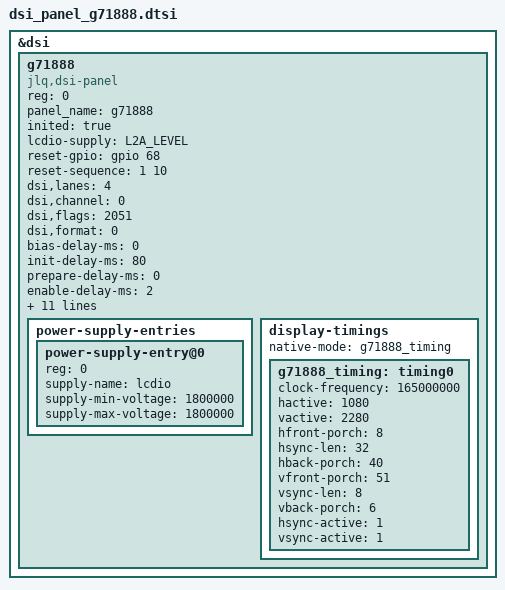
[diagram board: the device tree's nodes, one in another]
&dsi {
	g71888: g71888 {
		compatible = "jlq,dsi-panel";
		reg = <0>;
		panel_name = "g71888";
		status = "okay";
		inited = "true";

		lcdio-supply = <&L2A_LEVEL>;
		//lcdcore-supply = <&dldo13>;
		//bias-enp-gpio = <&gpio 2 0>;
		reset-gpio = <&gpio 68 0>;
		//bias-enn-gpio = <&gpio 0 0>;
		reset-sequence = <1 10>;
		pinctrl-names = "default";
		//pinctrl-0 = <&lcd_reset_pin>;

		dsi,lanes = <4>;
		dsi,channel = <0>;
		dsi,flags = <2051>;
		dsi,format = <0>;

		bias-delay-ms = <0>;
		init-delay-ms = <80>;
		prepare-delay-ms = <0>;
		enable-delay-ms = <2>;
		unprepare-delay-ms = <0>;
		disable-delay-ms = <2>;
		reset-delay-ms = <80>;
		width-mm = <120>;
		height-mm = <170>;
		pwm-names = "backlight";
		pwms = <&pwm0 0 32000>;

		panel-exit-sequence = [
			05 05 01 28
			05 78 01 10
		];

		panel-init-sequence = [
			39 01 04 df e0 94 31
			39 01 04 df e0 9e 51
			39 01 04 df e0 9f 48
			39 01 04 df e0 fb 0b
			39 01 04 df e4 a6 55
			39 01 04 df e0 94 00
			39 01 04 df e7 e3 aa
			39 01 04 df e7 e4 0a
			39 01 04 df e7 e5 22
			39 01 04 df e7 e6 aa
			39 01 04 df e7 e7 0a
			39 01 04 df e7 e8 22
			39 01 04 df e7 de d6
			39 01 04 df e7 d7 15
			39 01 04 df e7 d8 05
			39 01 04 df e4 84 10
			39 01 04 df e4 85 10
			39 01 04 df e4 60 12
			39 01 04 df e4 61 12
			39 01 04 df e4 65 12
			39 01 04 df e4 66 12
			39 01 04 df e7 bd 03
			39 01 04 df e7 be 03
			39 01 04 df e7 bf 03
			39 01 04 df e7 c0 03
			39 01 04 df e7 c1 03
			39 01 04 df e7 c2 03
			39 01 04 df e7 c3 03
			39 01 04 df e7 c4 03
			39 01 04 df e2 03 01
			39 01 04 df e2 04 01
			39 01 04 df e2 05 01
			39 01 04 df e2 0d 26
			39 01 04 df e2 0e 27
			39 01 04 df e2 08 a0
			39 01 04 df e2 0a cb
			39 01 04 df e2 07 a6
			39 01 04 df e2 09 cb
			39 01 04 df e2 16 00
			39 01 04 df e2 13 0e
			39 01 04 df e7 f4 49

			//gamma start
			39 01 04 df e4 20 04
			39 01 04 df e4 21 0b
			39 01 04 df e4 22 30
			39 01 04 df e4 23 3F
			39 01 04 df e4 24 0b
			39 01 04 df e4 25 14
			39 01 04 df e4 26 1C
			39 01 04 df e4 27 22
			39 01 04 df e4 28 2e
			39 01 04 df e4 29 38
			39 01 04 df e4 2a 2C
			39 01 04 df e4 2b 07
			39 01 04 df e4 2c 11
			39 01 04 df e4 2d 21
			39 01 04 df e4 2e 23
			39 01 04 df e4 2f 31
			39 01 04 df e4 30 38
			39 01 04 df e4 31 1f
			39 01 04 df e4 32 09
			39 01 04 df e4 33 14
			39 01 04 df e4 34 1e
			39 01 04 df e4 35 25
			39 01 04 df e4 36 2C
			39 01 04 df e4 37 35
			39 01 04 df e4 38 31
			39 01 04 df e4 39 35
			39 01 04 df e4 3a 37
			39 01 04 df e4 40 04
			39 01 04 df e4 41 0b
			39 01 04 df e4 42 30
			39 01 04 df e4 43 3F
			39 01 04 df e4 44 0b
			39 01 04 df e4 45 14
			39 01 04 df e4 46 1C
			39 01 04 df e4 47 22
			39 01 04 df e4 48 2e
			39 01 04 df e4 49 38
			39 01 04 df e4 4a 2C
			39 01 04 df e4 4b 07
			39 01 04 df e4 4c 11
			39 01 04 df e4 4d 21
			39 01 04 df e4 4e 23
			39 01 04 df e4 4f 31
			39 01 04 df e4 50 38
			39 01 04 df e4 51 1f
			39 01 04 df e4 52 09
			39 01 04 df e4 53 14
			39 01 04 df e4 54 1e
			39 01 04 df e4 55 25
			39 01 04 df e4 56 2C
			39 01 04 df e4 57 35
			39 01 04 df e4 58 31
			39 01 04 df e4 59 35
			39 01 04 df e4 5a 37
			//gamma end

			39 01 04 df e2 17 3e
			39 01 04 df e2 18 20
			39 01 04 df e2 48 80
			39 01 04 df e2 2f 00
			39 01 04 df e2 30 00
			39 01 04 df e2 3c 00
			39 01 04 df e2 3d 00
			39 01 04 df e0 06 06
			39 01 04 df e0 0a 88
			39 01 04 df e0 0b 04
			39 01 04 df e0 0c 48
			39 01 04 df e0 0d 00
			39 01 04 df e0 0e 38
			39 01 04 df e0 0f 04
			39 01 04 df e0 10 29
			39 01 04 df e0 11 09
			39 01 04 df e0 12 0e
			39 01 04 df e0 13 00
			39 01 04 df e0 14 e8
			39 01 04 df e0 15 08
			39 01 04 df e0 16 0a
			39 01 04 df e0 17 c1
			39 01 04 df e0 18 00
			39 01 04 df e0 19 20
			39 01 04 df e0 1a 02
			39 01 04 df e0 1b bf
			39 01 04 df e0 1c 09
			39 01 04 df e0 1d ff
			39 01 04 df e0 1e 01
			39 01 04 df e0 1f 10
			39 01 04 df e0 20 00
			39 01 04 df e0 26 bf
			39 01 04 df e0 28 00
			39 01 04 df e0 29 13
			39 01 04 df e0 2a 02
			39 01 04 df e1 92 1c
			39 01 04 df e1 93 01
			39 01 04 df e1 94 20
			39 01 04 df e1 95 01
			39 01 04 df e1 96 0c
			39 01 04 df e1 97 01
			39 01 04 df e1 b5 00
			39 01 04 df e1 a9 02
			39 01 04 df e1 aa 00
			39 01 04 df e1 ab 00
			39 01 04 df e1 ac 06
			39 01 04 df e1 ad 28
			39 01 04 df e1 ae 28
			39 01 04 df e1 af 28
			39 01 04 df e1 bd 0b
			39 01 04 df e1 be 0b
			39 01 04 df e1 99 4c
			39 01 04 df e1 b4 c4
			39 01 04 df e1 a8 00
			39 01 04 df e1 cb 1c
			39 01 04 df e1 cc 10
			39 01 04 df e1 ce 20
			39 01 04 df e1 cd 07
			39 01 04 df e1 98 03
			39 01 04 df e1 d6 03
			39 01 04 df e1 c9 09
			39 01 04 df e1 ed 10
			39 01 04 df e1 d9 00
			39 01 04 df e1 da 00
			39 01 04 df e1 db 00
			39 01 04 df e1 9b 10
			39 01 04 df e1 9c c0
			39 01 04 df e1 9d 04
			39 01 04 df e1 81 a0
			39 01 04 df e1 82 02
			39 01 04 df e1 83 00
			39 01 04 df e1 84 03
			39 01 04 df e1 85 60
			39 01 04 df e1 86 03
			39 01 04 df e1 9e 00
			39 01 04 df e1 9f 03
			39 01 04 df e1 a0 08
			39 01 04 df e1 b1 66
			39 01 04 df e1 ca 22
			39 01 04 df e1 87 e8
			39 01 04 df e1 88 08
			39 01 04 df e1 89 29
			39 01 04 df e1 8a 09
			39 01 04 df e1 d7 45
			39 01 04 df e1 d8 00
			39 01 04 df e1 89 a0
			39 01 04 df e1 8a 07
			39 01 04 df e1 8b 0e
			39 01 04 df e1 8c 00
			39 01 04 df e1 ee f0
			39 01 04 df e1 8f 88
			39 01 04 df e1 90 04
			39 01 04 df e7 af 77
			39 01 04 df e7 ae 02
			39 01 04 df e7 6a 40
			39 01 04 df e7 00 13
			39 01 04 df e7 01 10
			39 01 04 df e7 02 27
			39 01 04 df e7 73 11
			39 01 04 df e7 74 22
			39 01 04 df e7 75 11
			39 01 04 df e7 76 00
			39 01 04 df e7 77 22
			39 01 04 df e7 78 11
			39 01 04 df e7 79 00
			39 01 04 df e7 7a 00
			39 01 04 df e7 7b 11
			39 01 04 df e7 7c 22
			39 01 04 df e7 7d 00
			39 01 04 df e7 7e 11
			39 01 04 df e7 7f 22
			39 01 04 df e7 50 0c
			39 01 04 df e7 51 0d
			39 01 04 df e7 71 30
			39 01 04 df e7 5c 00
			39 01 04 df e7 5d 00
			39 01 04 df e7 60 10
			39 01 04 df e7 61 00
			39 01 04 df e7 62 00
			39 01 04 df e7 6b 00
			39 01 04 df e2 47 17
			39 01 04 df e7 70 28
			39 01 04 df e7 52 00
			39 01 04 df e7 0b 0c
			39 01 04 df e7 0c 66
			39 01 04 df e7 17 00
			39 01 04 df e7 0d 66
			39 01 04 df e7 0e c0
			39 01 04 df e7 18 00
			39 01 04 df e7 0f c0
			39 01 04 df e7 10 1a
			39 01 04 df e7 19 01
			39 01 04 df e7 11 0c
			39 01 04 df e7 12 66
			39 01 04 df e7 1a 00
			39 01 04 df e7 13 66
			39 01 04 df e7 14 c0
			39 01 04 df e7 1b 00
			39 01 04 df e7 15 c0
			39 01 04 df e7 16 1a
			39 01 04 df e7 1c 01
			39 01 04 df e7 1d 0c
			39 01 04 df e7 1e 66
			39 01 04 df e7 1f c0
			39 01 04 df e7 20 1a
			39 01 04 df e7 21 74
			39 01 04 df e7 22 ce
			39 01 04 df e7 23 00
			39 01 04 df e7 24 01
			39 01 04 df e7 25 11
			39 01 04 df e7 26 0c
			39 01 04 df e7 29 0c
			39 01 04 df e7 2c 00
			39 01 04 df e7 27 66
			39 01 04 df e7 2a 66
			39 01 04 df e7 2d 00
			39 01 04 df e7 28 c0
			39 01 04 df e7 2b c0
			39 01 04 df e7 2e 00
			39 01 04 df e7 2f 0a
			39 01 04 df e7 30 14
			39 01 04 df e7 35 00
			39 01 04 df e7 31 32
			39 01 04 df e7 32 3c
			39 01 04 df e7 36 00
			39 01 04 df e7 33 02
			39 01 04 df e7 34 1e
			39 01 04 df e7 37 02
			39 01 04 df e3 3e 17
			39 01 04 df e3 3f 61
			39 01 04 df e3 40 00
			39 01 04 df e3 41 71
			39 01 04 df e3 42 bb
			39 01 04 df e3 43 00
			39 01 04 df e3 56 cb
			39 01 04 df e3 57 15
			39 01 04 df e3 58 10
			39 01 04 df e3 16 03
			39 01 04 df e3 17 00
			39 01 04 df e3 18 36
			39 01 04 df e3 19 01
			39 01 04 df e3 22 69
			39 01 04 df e3 23 00
			39 01 04 df e3 24 29
			39 01 04 df e3 25 01
			39 01 04 df e3 2c 69
			39 01 04 df e3 2d 00
			39 01 04 df e3 2e 29
			39 01 04 df e3 2f 01
			39 01 04 df e3 36 69
			39 01 04 df e3 37 00
			39 01 04 df e3 38 29
			39 01 04 df e3 39 01
			39 01 04 df e9 02 69
			39 01 04 df e9 03 00
			39 01 04 df e9 04 29
			39 01 04 df e9 05 01
			39 01 04 df e3 02 61
			39 01 04 df e3 03 00
			39 01 04 df e3 04 61
			39 01 04 df e3 05 00
			39 01 04 df e3 00 07
			39 01 04 df e3 01 09
			39 01 04 df e3 06 01
			39 01 04 df e3 09 02
			39 01 04 df e3 1a 34
			39 01 04 df e3 1b 01
			39 01 04 df e8 2a 20
			39 01 04 df e8 2c 0c
			39 01 04 df e8 2f 04
			39 01 04 df e8 30 01
			39 01 04 df e8 31 80
			39 01 04 df e3 26 03
			39 01 04 df e3 27 09
			39 01 04 df e8 55 0c
			39 01 04 df e8 59 01
			39 01 04 df e3 30 03
			39 01 04 df e3 31 09
			39 01 04 df e8 7a 01
			39 01 04 df e8 7c 20
			39 01 04 df e8 7e 0c
			39 01 04 df e8 82 01
			39 01 04 df e3 3a 03
			39 01 04 df e3 3b 09
			39 01 04 df e8 a3 02
			39 01 04 df e8 a5 20
			39 01 04 df e8 a7 0c
			39 01 04 df e8 ab 01
			39 01 04 df e9 06 03
			39 01 04 df e9 07 09
			39 01 04 df e9 0a 03
			39 01 04 df e9 0c 20
			39 01 04 df e9 0e 0c
			39 01 04 df e9 12 01
			39 01 04 df e3 50 09
			39 01 04 df e3 51 80
			39 01 04 df e3 65 60
			39 01 04 df e8 d2 30
			39 01 04 df e8 d4 40
			39 01 04 df e8 d5 07
			39 01 04 df e8 d6 20
			39 01 04 df e8 d8 b0
			39 01 04 df e8 da cd
			39 01 04 df e8 db 7f
			39 01 04 df e8 dc 04
			39 01 04 df e8 dd f9
			39 01 04 df e8 de 5f
			39 01 04 df e8 df ff
			39 01 04 df e3 70 01
			39 01 04 df e3 71 82
			39 01 04 df e3 74 82
			39 01 04 df e3 75 80
			39 01 04 df e3 7a 00
			39 01 04 df e3 7c f0
			39 01 04 df e3 7d ff
			39 01 04 df e3 7e 0f
			39 01 04 df e3 80 f0
			39 01 04 df e3 bb 00
			39 01 04 df e3 bc 41
			39 01 04 df e3 bd 32
			39 01 04 df e3 be 23
			39 01 04 df e3 bf 14
			39 01 04 df e3 c1 c6
			39 01 04 df e3 8b 27
			39 01 04 df e3 8c 1e
			39 01 04 df e3 8d 27
			39 01 04 df e3 8e 1d
			39 01 04 df e3 8f 27
			39 01 04 df e3 90 06
			39 01 04 df e3 91 27
			39 01 04 df e3 92 27
			39 01 04 df e3 93 0a
			39 01 04 df e3 94 09
			39 01 04 df e3 95 08
			39 01 04 df e3 96 07
			39 01 04 df e3 97 27
			39 01 04 df e3 98 27
			39 01 04 df e3 99 27
			39 01 04 df e3 9a 27
			39 01 04 df e3 9b 27
			39 01 04 df e3 9c 15
			39 01 04 df e3 9d 10
			39 01 04 df e3 9e 11
			39 01 04 df e3 9f 27
			39 01 04 df e3 a0 16
			39 01 04 df e3 a1 17
			39 01 04 df e3 a2 1b
			39 01 04 df e3 a3 27
			39 01 04 df e3 a4 27
			39 01 04 df e3 a5 27
			39 01 04 df e3 a6 00
			39 01 04 df e3 a7 27
			39 01 04 df e3 a8 06
			39 01 04 df e3 a9 27
			39 01 04 df e3 aa 27
			39 01 04 df e3 ab 0a
			39 01 04 df e3 ac 09
			39 01 04 df e3 ad 08
			39 01 04 df e3 ae 07
			39 01 04 df e3 af 27
			39 01 04 df e3 b0 27
			39 01 04 df e3 b1 27
			39 01 04 df e3 b2 27
			39 01 04 df e3 b3 27
			39 01 04 df e3 b4 15
			39 01 04 df e3 b5 10
			39 01 04 df e3 b6 11
			39 01 04 df e3 b7 27
			39 01 04 df e3 b8 16
			39 01 04 df e3 b9 17
			39 01 04 df e3 ba 1b
			39 01 04 df e8 fb 01
			39 01 04 df e8 fc 03
			39 01 04 df e9 f3 01
			39 01 04 df e9 f4 01
			39 01 04 df e9 f6 0b
			39 01 04 df ea d8 10
			39 01 04 df ea da bc
			39 01 04 df ea db 0a
			39 01 04 df ea dc 00
			39 01 04 df ea dd 00
			39 01 04 df e9 a0 aa
			39 01 04 df e9 b8 aa
			39 01 04 df e8 f2 40
			39 01 04 df e8 f3 0f
			39 01 04 df e8 f4 00
			39 01 04 df e8 fd 40
			39 01 04 df e8 fe 0f
			39 01 04 df e8 ff 00
			39 01 04 df e8 f5 10
			39 01 04 df e3 c9 30
			39 01 04 df e3 ca 00
			39 01 04 df e3 cb 04
			39 01 04 df e3 cc 00
			39 01 04 df ec a7 30
			39 01 04 df ec a8 00
			39 01 04 df ec a9 04
			39 01 04 df ec aa 00
			39 01 04 df ec ab 30
			39 01 04 df ec ac 00
			39 01 04 df ec ad 04
			39 01 04 df ec ae 00
			39 01 04 df e0 95 1f
			39 01 04 df e2 89 0e
			39 01 04 df e1 00 9f
			39 01 04 df e1 01 00
			39 01 04 df e1 02 00
			39 01 04 df e1 00 00
			39 05 04 df e0 95 3f
			39 05 04 df e0 f7 1c
			39 05 04 df e0 fc 10
			39 01 04 df e0 fd 01//bist mode on 非自动刷图
			//39 01 04 df e0 ea 25//bist mode on 自动刷图
			39 01 04 df e0 31 f4
			39 01 04 df e0 42 48
			39 01 04 df e4 a0 94

			//CABC start
		//	39 01 04 df e2 82 01//03pwm  01 hight level  00close  53
		//	39 01 04 df e2 85 9a//

		//	39 01 04 df e6 70 df
		//	39 01 04 df e6 71 5f
		//	39 01 04 df e6 31 90
		//	39 01 04 df e6 3b 40
		//	39 01 04 df e6 36 00
		//	39 01 04 df e6 2c 03
		//	39 01 04 df e6 2d 90
		//	39 01 04 df e6 35 08
		//	39 01 04 df e6 33 ff//h
		//	39 01 04 df e6 34 f0//l  FFF
			//CABC end

			05 96 01 11
			05 32 01 29
		];

		power-supply-entries {
			#address-cells = <1>;
			#size-cells = <0>;

			power-supply-entry@0 {
				reg = <0>;
				supply-name = "lcdio";
				supply-min-voltage = <1800000>;
				supply-max-voltage = <1800000>;
			};
		};

		display-timings {
			native-mode = <&g71888_timing>;
			g71888_timing: timing0 {
				clock-frequency = <165000000>;
				hactive = <1080>;
				vactive = <2280>;
				hfront-porch = <8>;
				hsync-len = <32>;
				hback-porch = <40>;
				vfront-porch = <51>;
				vsync-len = <8>;
				vback-porch = <6>;
				hsync-active = <1>;
				vsync-active = <1>;
			};
		};
	};
};
